BU_: EBCM ADAS PCM EPS VSA SCM BDY XXX EPB EON

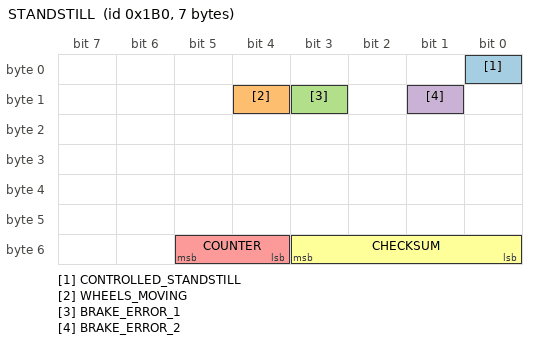
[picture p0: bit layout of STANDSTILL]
BO_ 432 STANDSTILL: 7 VSA
 SG_ CONTROLLED_STANDSTILL : 0|1@0+ (1,0) [0|1] "" EON
 SG_ WHEELS_MOVING : 12|1@0+ (1,0) [0|1] "" EON
 SG_ BRAKE_ERROR_1 : 11|1@0+ (1,0) [0|1] "" EON
 SG_ BRAKE_ERROR_2 : 9|1@0+ (1,0) [0|1] "" EON
 SG_ COUNTER : 53|2@0+ (1,0) [0|3] "" EON
 SG_ CHECKSUM : 51|4@0+ (1,0) [0|3] "" EON

CM_ SG_ 490 LONG_ACCEL "wheel speed derivative, noisy and zero snapping";
CM_ SG_ 506 AEB_REQ_1 "set for duration of suspected AEB event";
CM_ SG_ 773 PASS_AIRBAG_ON "Might just be indicator light";
CM_ SG_ 773 PASS_AIRBAG_OFF "Might just be indicator light";
CM_ SG_ 780 CRUISE_SPEED "255 = no speed";
CM_ SG_ 804 CRUISE_SPEED_PCM "255 = no speed";
CM_ SG_ 829 BEEP "beeps are pleasant, chimes are for warnngs etc...";

VAL_ 506 FCW 3 "fcw" 2 "fcw" 1 "fcw" 0 "no_fcw" ;
VAL_ 506 CHIME 4 "double_chime" 3 "single_chime" 2 "continuous_chime" 1 "repeating_chime" 0 "no_chime" ;
VAL_ 506 AEB_STATUS 3 "aeb_prepare" 2 "aeb_ready" 1 "aeb_braking" 0 "no_aeb" ;
VAL_ 780 CRUISE_SPEED 255 "no_speed" 252 "stopped" ;
VAL_ 780 HUD_LEAD 3 "acc_off" 2 "solid_car" 1 "dashed_car" 0 "no_car" ;
VAL_ 829 BEEP 3 "single_beep" 2 "triple_beep" 1 "repeated_beep" 0 "no_beep" ;
